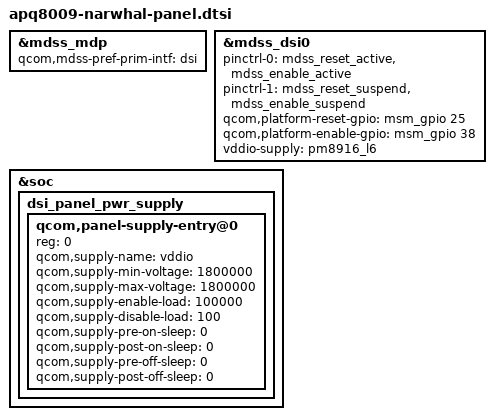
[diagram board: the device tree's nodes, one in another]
/* Copyright (c) 2017, LGE Inc. All rights reserved.
 *
 * This program is free software; you can redistribute it and/or modify
 * it under the terms of the GNU General Public License version 2 and
 * only version 2 as published by the Free Software Foundation.
 *
 * This program is distributed in the hope that it will be useful,
 * but WITHOUT ANY WARRANTY; without even the implied warranty of
 * MERCHANTABILITY or FITNESS FOR A PARTICULAR PURPOSE.  See the
 * GNU General Public License for more details.
 */

&mdss_mdp {
	qcom,mdss-pref-prim-intf = "dsi";
};

&mdss_dsi0 {
	pinctrl-names = "mdss_default", "mdss_sleep";
	pinctrl-0 = <&mdss_reset_active &mdss_enable_active>;
	pinctrl-1 = <&mdss_reset_suspend &mdss_enable_suspend>;

	qcom,platform-reset-gpio = <&msm_gpio 25 0>;
	qcom,platform-enable-gpio = <&msm_gpio 38 0>;

	vddio-supply = <&pm8916_l6>;
};

&soc {
	dsi_panel_pwr_supply: dsi_panel_pwr_supply {
		#address-cells = <1>;
		#size-cells = <0>;

		qcom,panel-supply-entry@0 {
			reg = <0>;
			qcom,supply-name = "vddio";
			qcom,supply-min-voltage = <1800000>;
			qcom,supply-max-voltage = <1800000>;
			qcom,supply-enable-load = <100000>;
			qcom,supply-disable-load = <100>;
			qcom,supply-pre-on-sleep = <0>;
			qcom,supply-post-on-sleep = <0>;
			qcom,supply-pre-off-sleep = <0>;
			qcom,supply-post-off-sleep = <0>;
		};
	};
};
